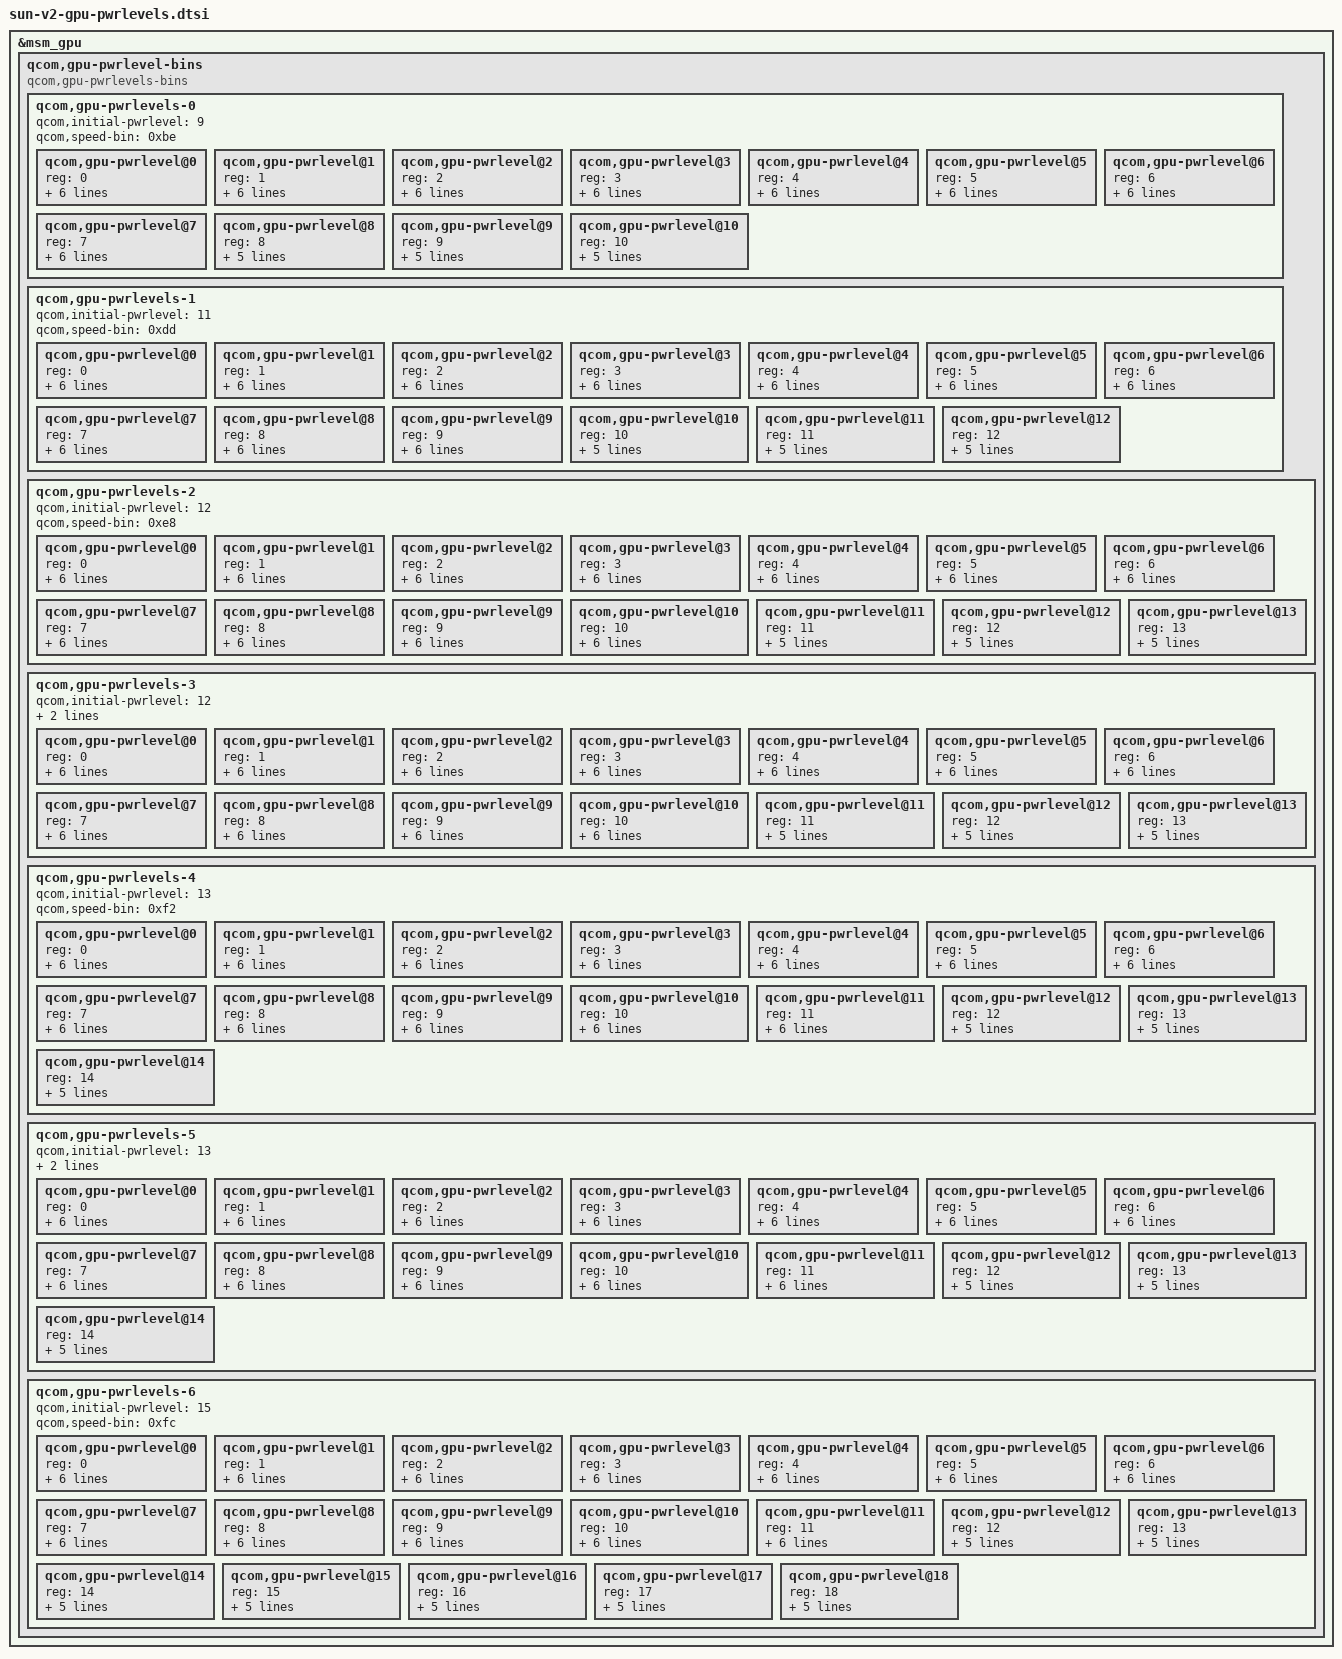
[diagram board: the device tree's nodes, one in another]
// SPDX-License-Identifier: BSD-3-Clause
/*
 * Copyright (c) 2023-2024 Qualcomm Innovation Center, Inc. All rights reserved.
 */

/* ACD Control register values */
#define ACD_LEVEL_TURBO_L4    0x88295ffd
#define ACD_LEVEL_TURBO_L3    0x88295ffd
#define ACD_LEVEL_TURBO_L1    0xa8295ffd
#define ACD_LEVEL_NOM_L1      0x882a5ffd
#define ACD_LEVEL_NOM         0x882a5ffd
#define ACD_LEVEL_SVS_L2      0x882a5ffd
#define ACD_LEVEL_SVS_L1      0xa82a5ffd
#define ACD_LEVEL_SVS_L0      0x882c5ffd
#define ACD_LEVEL_SVS         0xa82e5ffd
#define ACD_LEVEL_LOW_SVS_L1  0xc02e5ffd
#define ACD_LEVEL_LOW_SVS     0xc02e5ffd
#define ACD_LEVEL_LOW_SVS_D0  0xc8285ffd

&msm_gpu {
	/* Power levels */
	qcom,gpu-pwrlevel-bins {
		#address-cells = <1>;
		#size-cells = <0>;

		compatible = "qcom,gpu-pwrlevels-bins";

		/*
		 * The bins need to match based on speed bin first and then SKU.
		 * Keep pwrlevel bins sorted in ascending order of the fmax of the bins.
		 */
		qcom,gpu-pwrlevels-0 {
			#address-cells = <1>;
			#size-cells = <0>;

			qcom,initial-pwrlevel = <9>;
			qcom,speed-bin = <0xbe>;

			/* NOM */
			qcom,gpu-pwrlevel@0 {
				reg = <0>;
				qcom,gpu-freq = <900000000>;
				qcom,level = <RPMH_REGULATOR_LEVEL_NOM>;

				qcom,bus-freq = <11>;
				qcom,bus-min = <11>;
				qcom,bus-max = <11>;

				qcom,acd-level = <ACD_LEVEL_NOM>;
			};

			/* SVS_L2 */
			qcom,gpu-pwrlevel@1 {
				reg = <1>;
				qcom,gpu-freq = <832000000>;
				qcom,level = <RPMH_REGULATOR_LEVEL_SVS_L2>;

				qcom,bus-freq = <10>;
				qcom,bus-min = <7>;
				qcom,bus-max = <10>;

				qcom,acd-level = <ACD_LEVEL_SVS_L2>;
			};

			/* SVS_L1 */
			qcom,gpu-pwrlevel@2 {
				reg = <2>;
				qcom,gpu-freq = <734000000>;
				qcom,level = <RPMH_REGULATOR_LEVEL_SVS_L1>;

				qcom,bus-freq = <8>;
				qcom,bus-min = <6>;
				qcom,bus-max = <10>;

				qcom,acd-level = <ACD_LEVEL_SVS_L1>;
			};

			/* SVS_L0 */
			qcom,gpu-pwrlevel@3 {
				reg = <3>;
				qcom,gpu-freq = <660000000>;
				qcom,level = <RPMH_REGULATOR_LEVEL_SVS_L0>;

				qcom,bus-freq = <6>;
				qcom,bus-min = <4>;
				qcom,bus-max = <8>;

				qcom,acd-level = <ACD_LEVEL_SVS_L0>;
			};

			/* SVS */
			qcom,gpu-pwrlevel@4 {
				reg = <4>;
				qcom,gpu-freq = <607000000>;
				qcom,level = <RPMH_REGULATOR_LEVEL_SVS>;

				qcom,bus-freq = <6>;
				qcom,bus-min = <4>;
				qcom,bus-max = <8>;

				qcom,acd-level = <ACD_LEVEL_SVS>;
			};

			/* Low_SVS_L1 */
			qcom,gpu-pwrlevel@5 {
				reg = <5>;
				qcom,gpu-freq = <525000000>;
				qcom,level = <RPMH_REGULATOR_LEVEL_LOW_SVS_L1>;

				qcom,bus-freq = <4>;
				qcom,bus-min = <2>;
				qcom,bus-max = <6>;

				qcom,acd-level = <ACD_LEVEL_LOW_SVS_L1>;
			};

			/* Low_SVS */
			qcom,gpu-pwrlevel@6 {
				reg = <6>;
				qcom,gpu-freq = <443000000>;
				qcom,level = <RPMH_REGULATOR_LEVEL_LOW_SVS>;

				qcom,bus-freq = <4>;
				qcom,bus-min = <2>;
				qcom,bus-max = <6>;

				qcom,acd-level = <ACD_LEVEL_LOW_SVS>;
			};

			/* Low_SVS_D0 */
			qcom,gpu-pwrlevel@7 {
				reg = <7>;
				qcom,gpu-freq = <389000000>;
				qcom,level = <RPMH_REGULATOR_LEVEL_LOW_SVS_D0>;

				qcom,bus-freq = <4>;
				qcom,bus-min = <2>;
				qcom,bus-max = <6>;

				qcom,acd-level = <ACD_LEVEL_LOW_SVS_D0>;
			};

			/* Low_SVS_D1 */
			qcom,gpu-pwrlevel@8 {
				reg = <8>;
				qcom,gpu-freq = <342000000>;
				qcom,level = <RPMH_REGULATOR_LEVEL_LOW_SVS_D1>;

				qcom,bus-freq = <3>;
				qcom,bus-min = <2>;
				qcom,bus-max = <3>;
			};

			/* Low_SVS_D2 */
			qcom,gpu-pwrlevel@9 {
				reg = <9>;
				qcom,gpu-freq = <222000000>;
				qcom,level = <RPMH_REGULATOR_LEVEL_LOW_SVS_D2>;

				qcom,bus-freq = <2>;
				qcom,bus-min = <2>;
				qcom,bus-max = <2>;
			};

			/* Low_SVS_D3 */
			qcom,gpu-pwrlevel@10 {
				reg = <10>;
				qcom,gpu-freq = <160000000>;
				qcom,level = <RPMH_REGULATOR_LEVEL_LOW_SVS_D3>;

				qcom,bus-freq = <2>;
				qcom,bus-min = <2>;
				qcom,bus-max = <2>;
			};
		};

		qcom,gpu-pwrlevels-1 {
			#address-cells = <1>;
			#size-cells = <0>;

			qcom,initial-pwrlevel = <11>;
			qcom,speed-bin = <0xdd>;

			/* TURBO_L1 */
			qcom,gpu-pwrlevel@0 {
				reg = <0>;
				qcom,gpu-freq = <1050000000>;
				qcom,level = <RPMH_REGULATOR_LEVEL_TURBO_L1>;

				qcom,bus-freq = <11>;
				qcom,bus-min = <11>;
				qcom,bus-max = <11>;

				qcom,acd-level = <ACD_LEVEL_TURBO_L1>;
			};

			/* NOM_L1 */
			qcom,gpu-pwrlevel@1 {
				reg = <1>;
				qcom,gpu-freq = <967000000>;
				qcom,level = <RPMH_REGULATOR_LEVEL_NOM_L1>;

				qcom,bus-freq = <11>;
				qcom,bus-min = <11>;
				qcom,bus-max = <11>;

				qcom,acd-level = <ACD_LEVEL_NOM_L1>;
			};

			/* NOM */
			qcom,gpu-pwrlevel@2 {
				reg = <2>;
				qcom,gpu-freq = <900000000>;
				qcom,level = <RPMH_REGULATOR_LEVEL_NOM>;

				qcom,bus-freq = <10>;
				qcom,bus-min = <7>;
				qcom,bus-max = <10>;

				qcom,acd-level = <ACD_LEVEL_NOM>;
			};

			/* SVS_L2 */
			qcom,gpu-pwrlevel@3 {
				reg = <3>;
				qcom,gpu-freq = <832000000>;
				qcom,level = <RPMH_REGULATOR_LEVEL_SVS_L2>;

				qcom,bus-freq = <10>;
				qcom,bus-min = <7>;
				qcom,bus-max = <10>;

				qcom,acd-level = <ACD_LEVEL_SVS_L2>;
			};

			/* SVS_L1 */
			qcom,gpu-pwrlevel@4 {
				reg = <4>;
				qcom,gpu-freq = <734000000>;
				qcom,level = <RPMH_REGULATOR_LEVEL_SVS_L1>;

				qcom,bus-freq = <8>;
				qcom,bus-min = <6>;
				qcom,bus-max = <10>;

				qcom,acd-level = <ACD_LEVEL_SVS_L1>;
			};

			/* SVS_L0 */
			qcom,gpu-pwrlevel@5 {
				reg = <5>;
				qcom,gpu-freq = <660000000>;
				qcom,level = <RPMH_REGULATOR_LEVEL_SVS_L0>;

				qcom,bus-freq = <6>;
				qcom,bus-min = <4>;
				qcom,bus-max = <8>;

				qcom,acd-level = <ACD_LEVEL_SVS_L0>;
			};

			/* SVS */
			qcom,gpu-pwrlevel@6 {
				reg = <6>;
				qcom,gpu-freq = <607000000>;
				qcom,level = <RPMH_REGULATOR_LEVEL_SVS>;

				qcom,bus-freq = <6>;
				qcom,bus-min = <4>;
				qcom,bus-max = <8>;

				qcom,acd-level = <ACD_LEVEL_SVS>;
			};

			/* Low_SVS_L1 */
			qcom,gpu-pwrlevel@7 {
				reg = <7>;
				qcom,gpu-freq = <525000000>;
				qcom,level = <RPMH_REGULATOR_LEVEL_LOW_SVS_L1>;

				qcom,bus-freq = <4>;
				qcom,bus-min = <2>;
				qcom,bus-max = <6>;

				qcom,acd-level = <ACD_LEVEL_LOW_SVS_L1>;
			};

			/* Low_SVS */
			qcom,gpu-pwrlevel@8 {
				reg = <8>;
				qcom,gpu-freq = <443000000>;
				qcom,level = <RPMH_REGULATOR_LEVEL_LOW_SVS>;

				qcom,bus-freq = <4>;
				qcom,bus-min = <2>;
				qcom,bus-max = <6>;

				qcom,acd-level = <ACD_LEVEL_LOW_SVS>;
			};

			/* Low_SVS_D0 */
			qcom,gpu-pwrlevel@9 {
				reg = <9>;
				qcom,gpu-freq = <389000000>;
				qcom,level = <RPMH_REGULATOR_LEVEL_LOW_SVS_D0>;

				qcom,bus-freq = <4>;
				qcom,bus-min = <2>;
				qcom,bus-max = <6>;

				qcom,acd-level = <ACD_LEVEL_LOW_SVS_D0>;
			};

			/* Low_SVS_D1 */
			qcom,gpu-pwrlevel@10 {
				reg = <10>;
				qcom,gpu-freq = <342000000>;
				qcom,level = <RPMH_REGULATOR_LEVEL_LOW_SVS_D1>;

				qcom,bus-freq = <3>;
				qcom,bus-min = <2>;
				qcom,bus-max = <3>;
			};

			/* Low_SVS_D2 */
			qcom,gpu-pwrlevel@11 {
				reg = <11>;
				qcom,gpu-freq = <222000000>;
				qcom,level = <RPMH_REGULATOR_LEVEL_LOW_SVS_D2>;

				qcom,bus-freq = <2>;
				qcom,bus-min = <2>;
				qcom,bus-max = <2>;
			};

			/* Low_SVS_D3 */
			qcom,gpu-pwrlevel@12 {
				reg = <12>;
				qcom,gpu-freq = <160000000>;
				qcom,level = <RPMH_REGULATOR_LEVEL_LOW_SVS_D3>;

				qcom,bus-freq = <2>;
				qcom,bus-min = <2>;
				qcom,bus-max = <2>;
			};
		};

		qcom,gpu-pwrlevels-2 {
			#address-cells = <1>;
			#size-cells = <0>;

			qcom,initial-pwrlevel = <12>;
			qcom,speed-bin = <0xe8>;

			/* TURBO_L3 */
			qcom,gpu-pwrlevel@0 {
				reg = <0>;
				qcom,gpu-freq = <1100000000>;
				qcom,level = <RPMH_REGULATOR_LEVEL_TURBO_L3>;

				qcom,bus-freq = <11>;
				qcom,bus-min = <11>;
				qcom,bus-max = <11>;

				qcom,acd-level = <ACD_LEVEL_TURBO_L3>;
			};

			/* TURBO_L1 */
			qcom,gpu-pwrlevel@1 {
				reg = <1>;
				qcom,gpu-freq = <1050000000>;
				qcom,level = <RPMH_REGULATOR_LEVEL_TURBO_L1>;

				qcom,bus-freq = <11>;
				qcom,bus-min = <11>;
				qcom,bus-max = <11>;

				qcom,acd-level = <ACD_LEVEL_TURBO_L1>;
			};

			/* NOM_L1 */
			qcom,gpu-pwrlevel@2 {
				reg = <2>;
				qcom,gpu-freq = <967000000>;
				qcom,level = <RPMH_REGULATOR_LEVEL_NOM_L1>;

				qcom,bus-freq = <11>;
				qcom,bus-min = <11>;
				qcom,bus-max = <11>;

				qcom,acd-level = <ACD_LEVEL_NOM_L1>;
			};

			/* NOM */
			qcom,gpu-pwrlevel@3 {
				reg = <3>;
				qcom,gpu-freq = <900000000>;
				qcom,level = <RPMH_REGULATOR_LEVEL_NOM>;

				qcom,bus-freq = <10>;
				qcom,bus-min = <7>;
				qcom,bus-max = <10>;

				qcom,acd-level = <ACD_LEVEL_NOM>;
			};

			/* SVS_L2 */
			qcom,gpu-pwrlevel@4 {
				reg = <4>;
				qcom,gpu-freq = <832000000>;
				qcom,level = <RPMH_REGULATOR_LEVEL_SVS_L2>;

				qcom,bus-freq = <10>;
				qcom,bus-min = <7>;
				qcom,bus-max = <10>;

				qcom,acd-level = <ACD_LEVEL_SVS_L2>;
			};

			/* SVS_L1 */
			qcom,gpu-pwrlevel@5 {
				reg = <5>;
				qcom,gpu-freq = <734000000>;
				qcom,level = <RPMH_REGULATOR_LEVEL_SVS_L1>;

				qcom,bus-freq = <8>;
				qcom,bus-min = <6>;
				qcom,bus-max = <10>;

				qcom,acd-level = <ACD_LEVEL_SVS_L1>;
			};

			/* SVS_L0 */
			qcom,gpu-pwrlevel@6 {
				reg = <6>;
				qcom,gpu-freq = <660000000>;
				qcom,level = <RPMH_REGULATOR_LEVEL_SVS_L0>;

				qcom,bus-freq = <6>;
				qcom,bus-min = <4>;
				qcom,bus-max = <8>;

				qcom,acd-level = <ACD_LEVEL_SVS_L0>;
			};

			/* SVS */
			qcom,gpu-pwrlevel@7 {
				reg = <7>;
				qcom,gpu-freq = <607000000>;
				qcom,level = <RPMH_REGULATOR_LEVEL_SVS>;

				qcom,bus-freq = <6>;
				qcom,bus-min = <4>;
				qcom,bus-max = <8>;

				qcom,acd-level = <ACD_LEVEL_SVS>;
			};

			/* Low_SVS_L1 */
			qcom,gpu-pwrlevel@8 {
				reg = <8>;
				qcom,gpu-freq = <525000000>;
				qcom,level = <RPMH_REGULATOR_LEVEL_LOW_SVS_L1>;

				qcom,bus-freq = <4>;
				qcom,bus-min = <2>;
				qcom,bus-max = <6>;

				qcom,acd-level = <ACD_LEVEL_LOW_SVS_L1>;
			};

			/* Low_SVS */
			qcom,gpu-pwrlevel@9 {
				reg = <9>;
				qcom,gpu-freq = <443000000>;
				qcom,level = <RPMH_REGULATOR_LEVEL_LOW_SVS>;

				qcom,bus-freq = <4>;
				qcom,bus-min = <2>;
				qcom,bus-max = <6>;

				qcom,acd-level = <ACD_LEVEL_LOW_SVS>;
			};

			/* Low_SVS_D0 */
			qcom,gpu-pwrlevel@10 {
				reg = <10>;
				qcom,gpu-freq = <389000000>;
				qcom,level = <RPMH_REGULATOR_LEVEL_LOW_SVS_D0>;

				qcom,bus-freq = <4>;
				qcom,bus-min = <2>;
				qcom,bus-max = <6>;

				qcom,acd-level = <ACD_LEVEL_LOW_SVS_D0>;
			};

			/* Low_SVS_D1 */
			qcom,gpu-pwrlevel@11 {
				reg = <11>;
				qcom,gpu-freq = <342000000>;
				qcom,level = <RPMH_REGULATOR_LEVEL_LOW_SVS_D1>;

				qcom,bus-freq = <3>;
				qcom,bus-min = <2>;
				qcom,bus-max = <3>;
			};

			/* Low_SVS_D2 */
			qcom,gpu-pwrlevel@12 {
				reg = <12>;
				qcom,gpu-freq = <222000000>;
				qcom,level = <RPMH_REGULATOR_LEVEL_LOW_SVS_D2>;

				qcom,bus-freq = <2>;
				qcom,bus-min = <2>;
				qcom,bus-max = <2>;
			};

			/* Low_SVS_D3 */
			qcom,gpu-pwrlevel@13 {
				reg = <13>;
				qcom,gpu-freq = <160000000>;
				qcom,level = <RPMH_REGULATOR_LEVEL_LOW_SVS_D3>;

				qcom,bus-freq = <2>;
				qcom,bus-min = <2>;
				qcom,bus-max = <2>;
			};
		};

		qcom,gpu-pwrlevels-3 {
			#address-cells = <1>;
			#size-cells = <0>;

			qcom,initial-pwrlevel = <12>;
			qcom,sku-codes = <SKU_CODE(PCODE_UNKNOWN, FC_AA)
					SKU_CODE(PCODE_UNKNOWN, FC_AB)>;

			/* TURBO_L3 */
			qcom,gpu-pwrlevel@0 {
				reg = <0>;
				qcom,gpu-freq = <1100000000>;
				qcom,level = <RPMH_REGULATOR_LEVEL_TURBO_L3>;

				qcom,bus-freq = <11>;
				qcom,bus-min = <11>;
				qcom,bus-max = <11>;

				qcom,acd-level = <ACD_LEVEL_TURBO_L3>;
			};

			/* TURBO_L1 */
			qcom,gpu-pwrlevel@1 {
				reg = <1>;
				qcom,gpu-freq = <1050000000>;
				qcom,level = <RPMH_REGULATOR_LEVEL_TURBO_L1>;

				qcom,bus-freq = <11>;
				qcom,bus-min = <11>;
				qcom,bus-max = <11>;

				qcom,acd-level = <ACD_LEVEL_TURBO_L1>;
			};

			/* NOM_L1 */
			qcom,gpu-pwrlevel@2 {
				reg = <2>;
				qcom,gpu-freq = <967000000>;
				qcom,level = <RPMH_REGULATOR_LEVEL_NOM_L1>;

				qcom,bus-freq = <11>;
				qcom,bus-min = <11>;
				qcom,bus-max = <11>;

				qcom,acd-level = <ACD_LEVEL_NOM_L1>;
			};

			/* NOM */
			qcom,gpu-pwrlevel@3 {
				reg = <3>;
				qcom,gpu-freq = <900000000>;
				qcom,level = <RPMH_REGULATOR_LEVEL_NOM>;

				qcom,bus-freq = <10>;
				qcom,bus-min = <7>;
				qcom,bus-max = <10>;

				qcom,acd-level = <ACD_LEVEL_NOM>;
			};

			/* SVS_L2 */
			qcom,gpu-pwrlevel@4 {
				reg = <4>;
				qcom,gpu-freq = <832000000>;
				qcom,level = <RPMH_REGULATOR_LEVEL_SVS_L2>;

				qcom,bus-freq = <10>;
				qcom,bus-min = <7>;
				qcom,bus-max = <10>;

				qcom,acd-level = <ACD_LEVEL_SVS_L2>;
			};

			/* SVS_L1 */
			qcom,gpu-pwrlevel@5 {
				reg = <5>;
				qcom,gpu-freq = <734000000>;
				qcom,level = <RPMH_REGULATOR_LEVEL_SVS_L1>;

				qcom,bus-freq = <8>;
				qcom,bus-min = <6>;
				qcom,bus-max = <10>;

				qcom,acd-level = <ACD_LEVEL_SVS_L1>;
			};

			/* SVS_L0 */
			qcom,gpu-pwrlevel@6 {
				reg = <6>;
				qcom,gpu-freq = <660000000>;
				qcom,level = <RPMH_REGULATOR_LEVEL_SVS_L0>;

				qcom,bus-freq = <6>;
				qcom,bus-min = <4>;
				qcom,bus-max = <8>;

				qcom,acd-level = <ACD_LEVEL_SVS_L0>;
			};

			/* SVS */
			qcom,gpu-pwrlevel@7 {
				reg = <7>;
				qcom,gpu-freq = <607000000>;
				qcom,level = <RPMH_REGULATOR_LEVEL_SVS>;

				qcom,bus-freq = <6>;
				qcom,bus-min = <4>;
				qcom,bus-max = <8>;

				qcom,acd-level = <ACD_LEVEL_SVS>;
			};

			/* Low_SVS_L1 */
			qcom,gpu-pwrlevel@8 {
				reg = <8>;
				qcom,gpu-freq = <525000000>;
				qcom,level = <RPMH_REGULATOR_LEVEL_LOW_SVS_L1>;

				qcom,bus-freq = <4>;
				qcom,bus-min = <2>;
				qcom,bus-max = <6>;

				qcom,acd-level = <ACD_LEVEL_LOW_SVS_L1>;
			};

			/* Low_SVS */
			qcom,gpu-pwrlevel@9 {
				reg = <9>;
				qcom,gpu-freq = <443000000>;
				qcom,level = <RPMH_REGULATOR_LEVEL_LOW_SVS>;

				qcom,bus-freq = <4>;
				qcom,bus-min = <2>;
				qcom,bus-max = <6>;

				qcom,acd-level = <ACD_LEVEL_LOW_SVS>;
			};

			/* Low_SVS_D0 */
			qcom,gpu-pwrlevel@10 {
				reg = <10>;
				qcom,gpu-freq = <389000000>;
				qcom,level = <RPMH_REGULATOR_LEVEL_LOW_SVS_D0>;

				qcom,bus-freq = <4>;
				qcom,bus-min = <2>;
				qcom,bus-max = <6>;

				qcom,acd-level = <ACD_LEVEL_LOW_SVS_D0>;
			};

			/* Low_SVS_D1 */
			qcom,gpu-pwrlevel@11 {
				reg = <11>;
				qcom,gpu-freq = <342000000>;
				qcom,level = <RPMH_REGULATOR_LEVEL_LOW_SVS_D1>;

				qcom,bus-freq = <3>;
				qcom,bus-min = <2>;
				qcom,bus-max = <3>;
			};

			/* Low_SVS_D2 */
			qcom,gpu-pwrlevel@12 {
				reg = <12>;
				qcom,gpu-freq = <222000000>;
				qcom,level = <RPMH_REGULATOR_LEVEL_LOW_SVS_D2>;

				qcom,bus-freq = <2>;
				qcom,bus-min = <2>;
				qcom,bus-max = <2>;
			};

			/* Low_SVS_D3 */
			qcom,gpu-pwrlevel@13 {
				reg = <13>;
				qcom,gpu-freq = <160000000>;
				qcom,level = <RPMH_REGULATOR_LEVEL_LOW_SVS_D3>;

				qcom,bus-freq = <2>;
				qcom,bus-min = <2>;
				qcom,bus-max = <2>;
			};
		};

		qcom,gpu-pwrlevels-4 {
			#address-cells = <1>;
			#size-cells = <0>;

			qcom,initial-pwrlevel = <13>;
			qcom,speed-bin = <0xf2>;

			/* TURBO_MAX (OC) */
			qcom,gpu-pwrlevel@0 {
				reg = <0>;
				qcom,gpu-freq = <1200000000>;
				qcom,level = <RPMH_REGULATOR_LEVEL_SUPER_TURBO>;

				qcom,bus-freq = <11>;
				qcom,bus-min = <11>;
				qcom,bus-max = <11>;

				qcom,acd-level = <ACD_LEVEL_TURBO_L3>;
			};

			/* TURBO_L3 */
			qcom,gpu-pwrlevel@1 {
				reg = <1>;
				qcom,gpu-freq = <1200000000>;
				qcom,level = <RPMH_REGULATOR_LEVEL_TURBO_L3>;

				qcom,bus-freq = <11>;
				qcom,bus-min = <11>;
				qcom,bus-max = <11>;

				qcom,acd-level = <ACD_LEVEL_TURBO_L3>;
			};

			/* TURBO_L1 */
			qcom,gpu-pwrlevel@2 {
				reg = <2>;
				qcom,gpu-freq = <1050000000>;
				qcom,level = <RPMH_REGULATOR_LEVEL_TURBO_L1>;

				qcom,bus-freq = <11>;
				qcom,bus-min = <11>;
				qcom,bus-max = <11>;

				qcom,acd-level = <ACD_LEVEL_TURBO_L1>;
			};

			/* NOM_L1 */
			qcom,gpu-pwrlevel@3 {
				reg = <3>;
				qcom,gpu-freq = <967000000>;
				qcom,level = <RPMH_REGULATOR_LEVEL_NOM_L1>;

				qcom,bus-freq = <11>;
				qcom,bus-min = <11>;
				qcom,bus-max = <11>;

				qcom,acd-level = <ACD_LEVEL_NOM_L1>;
			};

			/* NOM */
			qcom,gpu-pwrlevel@4 {
				reg = <4>;
				qcom,gpu-freq = <900000000>;
				qcom,level = <RPMH_REGULATOR_LEVEL_NOM>;

				qcom,bus-freq = <10>;
				qcom,bus-min = <7>;
				qcom,bus-max = <10>;

				qcom,acd-level = <ACD_LEVEL_NOM>;
			};

			/* SVS_L2 */
			qcom,gpu-pwrlevel@5 {
				reg = <5>;
				qcom,gpu-freq = <832000000>;
				qcom,level = <RPMH_REGULATOR_LEVEL_SVS_L2>;

				qcom,bus-freq = <10>;
				qcom,bus-min = <7>;
				qcom,bus-max = <10>;

				qcom,acd-level = <ACD_LEVEL_SVS_L2>;
			};

			/* SVS_L1 */
			qcom,gpu-pwrlevel@6 {
				reg = <6>;
				qcom,gpu-freq = <734000000>;
				qcom,level = <RPMH_REGULATOR_LEVEL_SVS_L1>;

				qcom,bus-freq = <8>;
				qcom,bus-min = <6>;
				qcom,bus-max = <10>;

				qcom,acd-level = <ACD_LEVEL_SVS_L1>;
			};

			/* SVS_L0 */
			qcom,gpu-pwrlevel@7 {
				reg = <7>;
				qcom,gpu-freq = <660000000>;
				qcom,level = <RPMH_REGULATOR_LEVEL_SVS_L0>;

				qcom,bus-freq = <6>;
				qcom,bus-min = <4>;
				qcom,bus-max = <8>;

				qcom,acd-level = <ACD_LEVEL_SVS_L0>;
			};

			/* SVS */
			qcom,gpu-pwrlevel@8 {
				reg = <8>;
				qcom,gpu-freq = <607000000>;
				qcom,level = <RPMH_REGULATOR_LEVEL_SVS>;

				qcom,bus-freq = <6>;
				qcom,bus-min = <4>;
				qcom,bus-max = <8>;

				qcom,acd-level = <ACD_LEVEL_SVS>;
			};

			/* Low_SVS_L1 */
			qcom,gpu-pwrlevel@9 {
				reg = <9>;
				qcom,gpu-freq = <525000000>;
				qcom,level = <RPMH_REGULATOR_LEVEL_LOW_SVS_L1>;

				qcom,bus-freq = <4>;
				qcom,bus-min = <2>;
				qcom,bus-max = <6>;

				qcom,acd-level = <ACD_LEVEL_LOW_SVS_L1>;
			};

			/* Low_SVS */
			qcom,gpu-pwrlevel@10 {
				reg = <10>;
				qcom,gpu-freq = <443000000>;
				qcom,level = <RPMH_REGULATOR_LEVEL_LOW_SVS>;

				qcom,bus-freq = <4>;
				qcom,bus-min = <2>;
				qcom,bus-max = <6>;

				qcom,acd-level = <ACD_LEVEL_LOW_SVS>;
			};

			/* Low_SVS_D0 */
			qcom,gpu-pwrlevel@11 {
				reg = <11>;
				qcom,gpu-freq = <389000000>;
				qcom,level = <RPMH_REGULATOR_LEVEL_LOW_SVS_D0>;

				qcom,bus-freq = <4>;
				qcom,bus-min = <2>;
				qcom,bus-max = <6>;

				qcom,acd-level = <ACD_LEVEL_LOW_SVS_D0>;
			};

			/* Low_SVS_D1 */
			qcom,gpu-pwrlevel@12 {
				reg = <12>;
				qcom,gpu-freq = <342000000>;
				qcom,level = <RPMH_REGULATOR_LEVEL_LOW_SVS_D1>;

				qcom,bus-freq = <3>;
				qcom,bus-min = <2>;
				qcom,bus-max = <3>;
			};

			/* Low_SVS_D2 */
			qcom,gpu-pwrlevel@13 {
				reg = <13>;
				qcom,gpu-freq = <222000000>;
				qcom,level = <RPMH_REGULATOR_LEVEL_LOW_SVS_D2>;

				qcom,bus-freq = <2>;
				qcom,bus-min = <2>;
				qcom,bus-max = <2>;
			};

			/* Low_SVS_D3 */
			qcom,gpu-pwrlevel@14 {
				reg = <14>;
				qcom,gpu-freq = <160000000>;
				qcom,level = <RPMH_REGULATOR_LEVEL_LOW_SVS_D3>;

				qcom,bus-freq = <2>;
				qcom,bus-min = <2>;
				qcom,bus-max = <2>;
			};
		};

		qcom,gpu-pwrlevels-5 {
			#address-cells = <1>;
			#size-cells = <0>;

			qcom,initial-pwrlevel = <13>;
			qcom,sku-codes = <SKU_CODE(PCODE_UNKNOWN, FC_AC)
					SKU_CODE(PCODE_UNKNOWN, FC_UNKNOWN)>;

			/* TURBO_L4 */
			qcom,gpu-pwrlevel@0 {
				reg = <0>;
				qcom,gpu-freq = <1200000000>;
				qcom,level = <RPMH_REGULATOR_LEVEL_TURBO_L4>;

				qcom,bus-freq = <11>;
				qcom,bus-min = <11>;
				qcom,bus-max = <11>;

				qcom,acd-level = <ACD_LEVEL_TURBO_L4>;
			};

			/* TURBO_L3 */
			qcom,gpu-pwrlevel@1 {
				reg = <1>;
				qcom,gpu-freq = <1100000000>;
				qcom,level = <RPMH_REGULATOR_LEVEL_TURBO_L3>;

				qcom,bus-freq = <11>;
				qcom,bus-min = <11>;
				qcom,bus-max = <11>;

				qcom,acd-level = <ACD_LEVEL_TURBO_L3>;
			};

			/* TURBO_L1 */
			qcom,gpu-pwrlevel@2 {
				reg = <2>;
				qcom,gpu-freq = <1050000000>;
				qcom,level = <RPMH_REGULATOR_LEVEL_TURBO_L1>;

				qcom,bus-freq = <11>;
				qcom,bus-min = <11>;
				qcom,bus-max = <11>;

				qcom,acd-level = <ACD_LEVEL_TURBO_L1>;
			};

			/* NOM_L1 */
			qcom,gpu-pwrlevel@3 {
				reg = <3>;
				qcom,gpu-freq = <967000000>;
				qcom,level = <RPMH_REGULATOR_LEVEL_NOM_L1>;

				qcom,bus-freq = <10>;
				qcom,bus-min = <10>;
				qcom,bus-max = <11>;

				qcom,acd-level = <ACD_LEVEL_NOM_L1>;
			};

			/* NOM */
			qcom,gpu-pwrlevel@4 {
				reg = <4>;
				qcom,gpu-freq = <900000000>;
				qcom,level = <RPMH_REGULATOR_LEVEL_NOM>;

				qcom,bus-freq = <10>;
				qcom,bus-min = <7>;
				qcom,bus-max = <10>;

				qcom,acd-level = <ACD_LEVEL_NOM>;
			};

			/* SVS_L2 */
			qcom,gpu-pwrlevel@5 {
				reg = <5>;
				qcom,gpu-freq = <832000000>;
				qcom,level = <RPMH_REGULATOR_LEVEL_SVS_L2>;

				qcom,bus-freq = <10>;
				qcom,bus-min = <7>;
				qcom,bus-max = <10>;

				qcom,acd-level = <ACD_LEVEL_SVS_L2>;
			};

			/* SVS_L1 */
			qcom,gpu-pwrlevel@6 {
				reg = <6>;
				qcom,gpu-freq = <734000000>;
				qcom,level = <RPMH_REGULATOR_LEVEL_SVS_L1>;

				qcom,bus-freq = <8>;
				qcom,bus-min = <6>;
				qcom,bus-max = <10>;

				qcom,acd-level = <ACD_LEVEL_SVS_L1>;
			};

			/* SVS_L0 */
			qcom,gpu-pwrlevel@7 {
				reg = <7>;
				qcom,gpu-freq = <660000000>;
				qcom,level = <RPMH_REGULATOR_LEVEL_SVS_L0>;

				qcom,bus-freq = <6>;
				qcom,bus-min = <4>;
				qcom,bus-max = <8>;

				qcom,acd-level = <ACD_LEVEL_SVS_L0>;
			};

			/* SVS */
			qcom,gpu-pwrlevel@8 {
				reg = <8>;
				qcom,gpu-freq = <607000000>;
				qcom,level = <RPMH_REGULATOR_LEVEL_SVS>;

				qcom,bus-freq = <6>;
				qcom,bus-min = <4>;
				qcom,bus-max = <8>;

				qcom,acd-level = <ACD_LEVEL_SVS>;
			};

			/* Low_SVS_L1 */
			qcom,gpu-pwrlevel@9 {
				reg = <9>;
				qcom,gpu-freq = <525000000>;
				qcom,level = <RPMH_REGULATOR_LEVEL_LOW_SVS_L1>;

				qcom,bus-freq = <4>;
				qcom,bus-min = <2>;
				qcom,bus-max = <6>;

				qcom,acd-level = <ACD_LEVEL_LOW_SVS_L1>;
			};

			/* Low_SVS */
			qcom,gpu-pwrlevel@10 {
				reg = <10>;
				qcom,gpu-freq = <443000000>;
				qcom,level = <RPMH_REGULATOR_LEVEL_LOW_SVS>;

				qcom,bus-freq = <4>;
				qcom,bus-min = <2>;
				qcom,bus-max = <6>;

				qcom,acd-level = <ACD_LEVEL_LOW_SVS>;
			};

			/* Low_SVS_D0 */
			qcom,gpu-pwrlevel@11 {
				reg = <11>;
				qcom,gpu-freq = <389000000>;
				qcom,level = <RPMH_REGULATOR_LEVEL_LOW_SVS_D0>;

				qcom,bus-freq = <4>;
				qcom,bus-min = <2>;
				qcom,bus-max = <6>;

				qcom,acd-level = <ACD_LEVEL_LOW_SVS_D0>;
			};

			/* Low_SVS_D1 */
			qcom,gpu-pwrlevel@12 {
				reg = <12>;
				qcom,gpu-freq = <342000000>;
				qcom,level = <RPMH_REGULATOR_LEVEL_LOW_SVS_D1>;

				qcom,bus-freq = <3>;
				qcom,bus-min = <2>;
				qcom,bus-max = <3>;
			};

			/* Low_SVS_D2 */
			qcom,gpu-pwrlevel@13 {
				reg = <13>;
				qcom,gpu-freq = <222000000>;
				qcom,level = <RPMH_REGULATOR_LEVEL_LOW_SVS_D2>;

				qcom,bus-freq = <2>;
				qcom,bus-min = <2>;
				qcom,bus-max = <2>;
			};

			/* Low_SVS_D3 */
			qcom,gpu-pwrlevel@14 {
				reg = <14>;
				qcom,gpu-freq = <160000000>;
				qcom,level = <RPMH_REGULATOR_LEVEL_LOW_SVS_D3>;

				qcom,bus-freq = <2>;
				qcom,bus-min = <2>;
				qcom,bus-max = <2>;
			};
		};

		qcom,gpu-pwrlevels-6 {
			#address-cells = <1>;
			#size-cells = <0>;

			qcom,initial-pwrlevel = <15>;
			qcom,speed-bin = <0xfc>;

			qcom,gpu-pwrlevel@0 {
				reg = <0>;
				qcom,gpu-freq = <1200000000>;
				qcom,level = <448>;
				qcom,bus-freq = <11>;
				qcom,bus-min = <11>;
				qcom,bus-max = <11>;
				qcom,acd-level = <0x802f5ffd>;
			};

			qcom,gpu-pwrlevel@1 {
				reg = <1>;
				qcom,gpu-freq = <1200000000>;
				qcom,level = <448>;
				qcom,bus-freq = <11>;
				qcom,bus-min = <11>;
				qcom,bus-max = <11>;
				qcom,acd-level = <0x802f5ffd>;
			};

			qcom,gpu-pwrlevel@2 {
				reg = <2>;
				qcom,gpu-freq = <1050000000>;
				qcom,level = <416>;
				qcom,bus-freq = <9>;
				qcom,bus-min = <8>;
				qcom,bus-max = <10>;
				qcom,acd-level = <0xa8295ffd>;
			};

			qcom,gpu-pwrlevel@3 {
				reg = <3>;
				qcom,gpu-freq = <967000000>;
				qcom,level = <320>;
				qcom,bus-freq = <7>;
				qcom,bus-min = <6>;
				qcom,bus-max = <9>;
				qcom,acd-level = <0x882b5ffd>;
			};

			qcom,gpu-pwrlevel@4 {
				reg = <4>;
				qcom,gpu-freq = <902000000>;
				qcom,level = <256>;
				qcom,bus-freq = <7>;
				qcom,bus-min = <6>;
				qcom,bus-max = <9>;
				qcom,acd-level = <0xa82b5ffd>;
			};

			qcom,gpu-pwrlevel@5 {
				reg = <5>;
				qcom,gpu-freq = <826000000>;
				qcom,level = <224>;
				qcom,bus-freq = <7>;
				qcom,bus-min = <6>;
				qcom,bus-max = <9>;
				qcom,acd-level = <0xa82e5ffd>;
			};

			qcom,gpu-pwrlevel@6 {
				reg = <6>;
				qcom,gpu-freq = <726000000>;
				qcom,level = <192>;
				qcom,bus-freq = <5>;
				qcom,bus-min = <5>;
				qcom,bus-max = <9>;
				qcom,acd-level = <0xe0295ffd>;
			};

			qcom,gpu-pwrlevel@7 {
				reg = <7>;
				qcom,gpu-freq = <646000000>;
				qcom,level = <144>;
				qcom,bus-freq = <5>;
				qcom,bus-min = <3>;
				qcom,bus-max = <7>;
				qcom,acd-level = <0xc02c5ffd>;
			};

			qcom,gpu-pwrlevel@8 {
				reg = <8>;
				qcom,gpu-freq = <578000000>;
				qcom,level = <128>;
				qcom,bus-freq = <3>;
				qcom,bus-min = <3>;
				qcom,bus-max = <7>;
				qcom,acd-level = <0xe8295ffd>;
			};

			qcom,gpu-pwrlevel@9 {
				reg = <9>;
				qcom,gpu-freq = <539000000>;
				qcom,level = <96>;
				qcom,bus-freq = <3>;
				qcom,bus-min = <2>;
				qcom,bus-max = <5>;
				qcom,acd-level = <0xc82b5ffd>;
			};

			qcom,gpu-pwrlevel@10 {
				reg = <10>;
				qcom,gpu-freq = <500000000>;
				qcom,level = <80>;
				qcom,bus-freq = <3>;
				qcom,bus-min = <2>;
				qcom,bus-max = <5>;
				qcom,acd-level = <0xe82e5ffd>;
			};

			qcom,gpu-pwrlevel@11 {
				reg = <11>;
				qcom,gpu-freq = <461000000>;
				qcom,level = <76>;
				qcom,bus-freq = <3>;
				qcom,bus-min = <2>;
				qcom,bus-max = <5>;
				qcom,acd-level = <0xe82e5ffd>;
			};

			qcom,gpu-pwrlevel@12 {
				reg = <12>;
				qcom,gpu-freq = <422000000>;
				qcom,level = <64>;
				qcom,bus-freq = <3>;
				qcom,bus-min = <2>;
				qcom,bus-max = <5>;
			};

			qcom,gpu-pwrlevel@13 {
				reg = <13>;
				qcom,gpu-freq = <382000000>;
				qcom,level = <60>;
				qcom,bus-freq = <2>;
				qcom,bus-min = <1>;
				qcom,bus-max = <2>;
			};

			qcom,gpu-pwrlevel@14 {
				reg = <14>;
				qcom,gpu-freq = <342000000>;
				qcom,level = <56>;
				qcom,bus-freq = <2>;
				qcom,bus-min = <1>;
				qcom,bus-max = <2>;
			};

			qcom,gpu-pwrlevel@15 {
				reg = <15>;
				qcom,gpu-freq = <282000000>;
				qcom,level = <54>;
				qcom,bus-freq = <2>;
				qcom,bus-min = <1>;
				qcom,bus-max = <2>;
			};

			qcom,gpu-pwrlevel@16 {
				reg = <16>;
				qcom,gpu-freq = <222000000>;
				qcom,level = <52>;
				qcom,bus-freq = <2>;
				qcom,bus-min = <1>;
				qcom,bus-max = <2>;
			};

			qcom,gpu-pwrlevel@17 {
				reg = <17>;
				qcom,gpu-freq = <191000000>;
				qcom,level = <51>;
				qcom,bus-freq = <2>;
				qcom,bus-min = <1>;
				qcom,bus-max = <2>;
			};

			qcom,gpu-pwrlevel@18 {
				reg = <18>;
				qcom,gpu-freq = <160000000>;
				qcom,level = <50>;
				qcom,bus-freq = <1>;
				qcom,bus-min = <1>;
				qcom,bus-max = <1>;
			};
		};
	};
};
